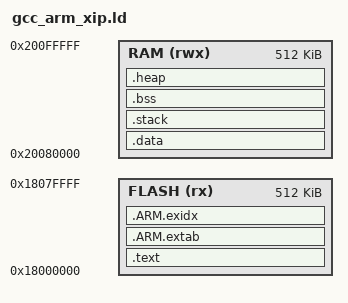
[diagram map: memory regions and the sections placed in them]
/* Linker script to configure memory regions. */
MEMORY
{
  FLASH (rx)  : ORIGIN = 0x18000000, LENGTH = 512K
  RAM   (rwx) : ORIGIN = 0x20080000, LENGTH = 512K
}

/* Linker script to place sections and symbol values. Should be used together
 * with other linker script that defines memory regions FLASH and RAM.
 * It references following symbols, which must be defined in code:
 *   Reset_Handler : Entry of reset handler
 *
 * It defines following symbols, which code can use without definition:
 *   __exidx_start
 *   __exidx_end
 *   __copy_table_start__
 *   __copy_table_end__
 *   __zero_table_start__
 *   __zero_table_end__
 *   __etext
 *   __data_start__
 *   __preinit_array_start
 *   __preinit_array_end
 *   __init_array_start
 *   __init_array_end
 *   __fini_array_start
 *   __fini_array_end
 *   __data_end__
 *   __bss_start__
 *   __bss_end__
 *   __end__
 *   end
 *   __HeapLimit
 *   __StackLimit
 *   __StackTop
 *   __stack
 */
ENTRY(Reset_Handler)

_system_stack_size = 0x400;
NUM_INTERRUPTS = 214;

SECTIONS
{
    .text :
    {
        . = ALIGN(4);
        KEEP(*(.vectors))            /* Startup code */
        . = ALIGN(4);
        *(.text)                        /* remaining code */
        *(.text.*)                      /* remaining code */
        *(.rodata)                      /* read-only data (constants) */
        *(.rodata*)
        *(.glue_7)
        *(.glue_7t)
        *(.gnu.linkonce.t*)

        /* section information for finsh shell */
        . = ALIGN(4);
        __fsymtab_start = .;
        KEEP(*(FSymTab))
        __fsymtab_end = .;
        . = ALIGN(4);
        __vsymtab_start = .;
        KEEP(*(VSymTab))
        __vsymtab_end = .;
        . = ALIGN(4);

        /* section information for initial. */
        . = ALIGN(4);
        __rt_init_start = .;
        KEEP(*(SORT(.rti_fn*)))
        __rt_init_end = .;
        . = ALIGN(4);
    } > FLASH

    .ARM.extab :
    {
        *(.ARM.extab* .gnu.linkonce.armextab.*)
    } > FLASH

    __exidx_start = .;
    .ARM.exidx :
    {
        *(.ARM.exidx* .gnu.linkonce.armexidx.*)
    } > FLASH
    __exidx_end = .;

    /* To copy multiple ROM to RAM sections,
     * uncomment .copy.table section and,
     * define __STARTUP_COPY_MULTIPLE in startup_ARMCMx.S */
    /*
    .copy.table :
    {
        . = ALIGN(4);
        __copy_table_start__ = .;
        LONG (__etext)
        LONG (__data_start__)
        LONG (__data_end__ - __data_start__)
        LONG (__etext2)
        LONG (__data2_start__)
        LONG (__data2_end__ - __data2_start__)
        __copy_table_end__ = .;
    } > FLASH
    */

    /* To clear multiple BSS sections,
     * uncomment .zero.table section and,
     * define __STARTUP_CLEAR_BSS_MULTIPLE in startup_ARMCMx.S */
    /*
    .zero.table :
    {
        . = ALIGN(4);
        __zero_table_start__ = .;
        LONG (__bss_start__)
        LONG (__bss_end__ - __bss_start__)
        LONG (__bss2_start__)
        LONG (__bss2_end__ - __bss2_start__)
        __zero_table_end__ = .;
    } > FLASH
    */

    /* must be cacheline align */
    __etext = ALIGN (32);

    .data : AT (__etext)
    {
        __data_start__ = .;
        __vector_remap__ = .;
        . = . + (NUM_INTERRUPTS * 4);	/* flash vector remap */
        *(vtable)
        *(.data*)

        . = ALIGN(4);
        /* preinit data */
        PROVIDE_HIDDEN (__preinit_array_start = .);
        KEEP(*(.preinit_array))
        PROVIDE_HIDDEN (__preinit_array_end = .);

        . = ALIGN(4);
        /* init data */
        PROVIDE_HIDDEN (__init_array_start = .);
        KEEP(*(SORT(.init_array.*)))
        KEEP(*(.init_array))
        PROVIDE_HIDDEN (__init_array_end = .);


        . = ALIGN(4);
        /* finit data */
        PROVIDE_HIDDEN (__fini_array_start = .);
        KEEP(*(SORT(.fini_array.*)))
        KEEP(*(.fini_array))
        PROVIDE_HIDDEN (__fini_array_end = .);

        KEEP(*(.jcr*))
        . = ALIGN(4);
        /* All data end */
        __data_end__ = .;

    } > RAM

    .stack :
    {
        . = . + _system_stack_size;
        . = ALIGN(4);
        _estack = .;
    } > RAM

    .bss :
    {
        . = ALIGN(4);
        __bss_start__ = .;
        *(.bss*)
        *(COMMON)
        . = ALIGN(4);
        __bss_end__ = .;
    } > RAM

	.heap (COPY):
	{
		__end__ = .;
		PROVIDE(end = .);
		*(.heap*)
		__HeapLimit = .;
	} > RAM
}
